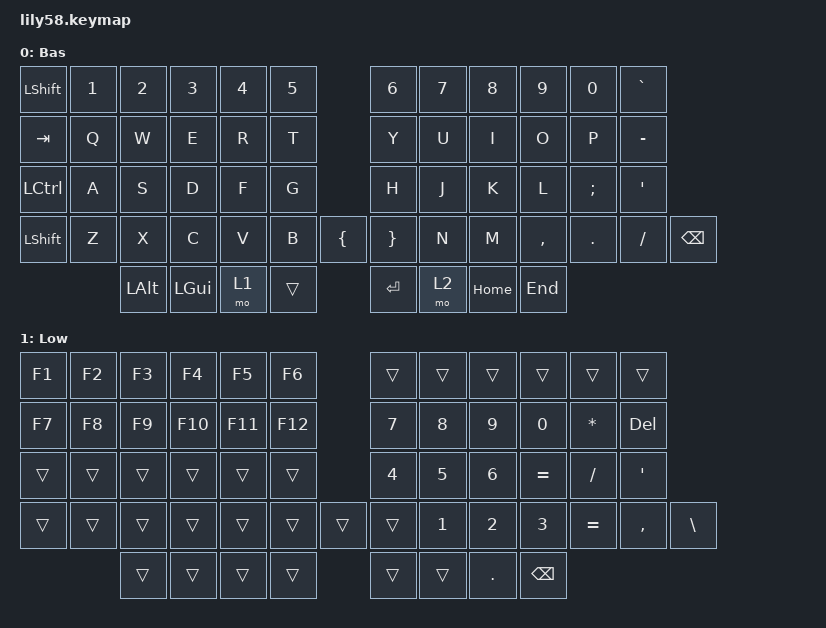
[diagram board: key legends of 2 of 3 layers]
/*
 * Copyright (c) 2020 The ZMK Contributors
 *
 * SPDX-License-Identifier: MIT
 */

#include <behaviors.dtsi>
#include <dt-bindings/zmk/keys.h>
#include <dt-bindings/zmk/bt.h>
#include <dt-bindings/zmk/ext_power.h>

/ {
    keymap {
        compatible = "zmk,keymap";

        // ==========================================
        // СЛОЙ 0: Базовый (Третья картинка)
        // ==========================================
        default_layer {
            display-name = "Bas";
            bindings = <
// ЛЕВАЯ РУКА (6 КОЛОНОК)                                              ПРАВАЯ РУКА (6 КОЛОНОК)
&kp LSHFT &kp N1    &kp N2    &kp N3    &kp N4    &kp N5         &kp N6    &kp N7    &kp N8    &kp N9    &kp N0    &kp GRAVE
&kp TAB   &kp Q     &kp W     &kp E     &kp R     &kp T          &kp Y     &kp U     &kp I     &kp O     &kp P     &kp MINUS
&kp LCTRL &kp A     &kp S     &kp D     &kp F     &kp G          &kp H     &kp J     &kp K     &kp L     &kp SEMI  &kp SQT
&kp LSHFT &kp Z     &kp X     &kp C     &kp V     &kp B     &kp LBRC &kp RBRC &kp N     &kp M     &kp COMMA &kp DOT   &kp FSLH  &kp BSPC

// ТАМБ-КЛАСТЕР (ЛЕВАЯ)                                                ТАМБ-КЛАСТЕР (ПРАВАЯ)
                    &kp LALT  &kp LGUI  &mo 1     &trans         &kp RET   &mo 2     &kp HOME  &kp END
            >;

            sensor-bindings = <&inc_dec_kp C_VOL_UP C_VOL_DN>;
        };

        // ==========================================
        // СЛОЙ 1: Fn / Numpad (Вторая картинка)
        // ==========================================
        lower_layer {
            display-name = "Low";
            bindings = <
// ЛЕВАЯ РУКА (6 КОЛОНОК)                                              ПРАВАЯ РУКА (6 КОЛОНОК)
&kp F1    &kp F2    &kp F3    &kp F4    &kp F5    &kp F6         &trans    &trans    &trans    &trans    &trans    &trans
&kp F7    &kp F8    &kp F9    &kp F10   &kp F11   &kp F12        &kp N7    &kp N8    &kp N9    &kp N0    &kp STAR  &kp DEL
&trans    &trans    &trans    &trans    &trans    &trans         &kp N4    &kp N5    &kp N6    &kp EQUAL &kp FSLH  &kp SQT
&trans    &trans    &trans    &trans    &trans    &trans    &trans &trans &kp N1    &kp N2    &kp N3    &kp EQUAL &kp COMMA &kp BSLH

// ТАМБ-КЛАСТЕР (ЛЕВАЯ)                                                ТАМБ-КЛАСТЕР (ПРАВАЯ)
                    &trans    &trans    &trans    &trans         &trans    &trans    &kp DOT   &kp BSPC
            >;

            sensor-bindings = <&inc_dec_kp C_VOL_UP C_VOL_DN>;
        };

        // ==========================================
        // СЛОЙ 2: Навигация (Первая картинка)
        // ==========================================
        raise_layer {
            display-name = "Rai";
            bindings = <
// ЛЕВАЯ РУКА (6 КОЛОНОК)                                              ПРАВАЯ РУКА (6 КОЛОНОК)
&trans    &trans    &trans    &trans    &trans    &trans         &trans    &trans    &trans    &trans    &trans    &trans
&kp TAB   &kp TAB   &kp W     &kp LEFT  &trans    &trans         &trans    &trans    &trans    &trans    &kp RIGHT &kp L
&kp BSPC  &kp UP    &kp DEL   &trans    &trans    &trans         &trans    &trans    &trans    &trans    &kp LCTRL &kp S
&kp LEFT  &kp DOWN  &kp RIGHT &trans    &trans    &trans    &kp N0   &trans    &trans    &kp LCTRL &kp LSHFT &kp S     &kp BSLH

// ТАМБ-КЛАСТЕР (ЛЕВАЯ)                                                ТАМБ-КЛАСТЕР (ПРАВАЯ)
                    &kp ESC   &trans    &trans    &trans         &trans    &trans    &kp PG_UP &kp PG_DN
            >;

            sensor-bindings = <&inc_dec_kp C_VOL_UP C_VOL_DN>;
        };

        extra_1 {
            status = "reserved";
        };

        extra_2 {
            status = "reserved";
        };

        extra_3 {
            status = "reserved";
        };
    };
};
